# EFR32BG22 register map
Vendor: Silicon Labs; Series: EFR32; File version: C
Registers are 32-bit, read-write, reset 0x0 unless marked. A register's access mark holds for its fields unless they carry their own. Offsets are from the block's base; [hi:lo] are bit positions; lines under a group give offsets from that group; {n}, {i} and the like mark numbered series; 'fields as' and 'values as' point back to an identical list.

## GPIO_S — GPIO_S Registers
Base 0x4003C000
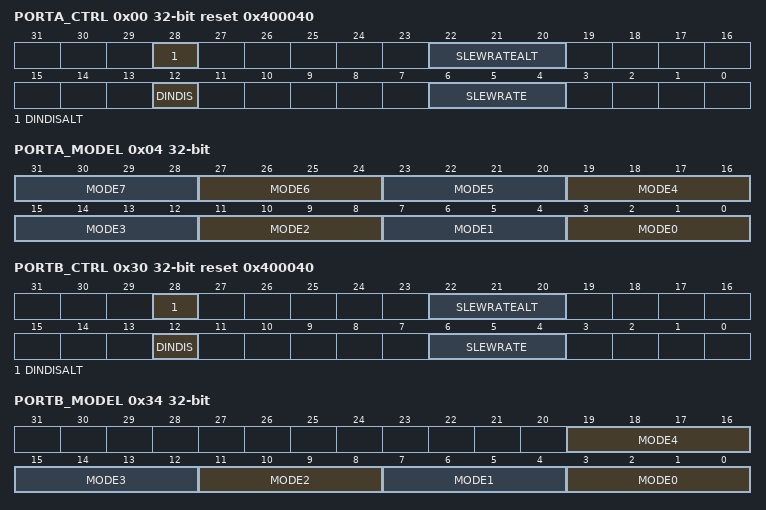
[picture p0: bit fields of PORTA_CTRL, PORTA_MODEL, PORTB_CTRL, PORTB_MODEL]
0x00 PORTA_CTRL reset 0x400040 — Port control
  [28] DINDISALT — Data In Disable Alt
  [22:20] SLEWRATEALT
  [12] DINDIS — Data In Disable
  [6:4] SLEWRATE
0x04 PORTA_MODEL — mode low
  [all] fields
    0=DISABLED (Input disabled. Pullup if DOUT is set.); 1=INPUT (Input enabled. Filter if DOUT is set.); 2=INPUTPULL (Input enabled. DOUT determines pull direction.); 3=INPUTPULLFILTER (Input enabled with filter. DOUT determines pull direction.); 4=PUSHPULL (Push-pull output.); 5=PUSHPULLALT (Push-pull using alternate control.); 6=WIREDOR (Wired-or output.); 7=WIREDORPULLDOWN (Wired-or output with pull-down.); 8=WIREDAND (Open-drain output.); 9=WIREDANDFILTER (Open-drain output with filter.); 10=WIREDANDPULLUP (Open-drain output with pullup.); 11=WIREDANDPULLUPFILTER (Open-drain output with filter and pullup.); 12=WIREDANDALT (Open-drain output using alternate control.); 13=WIREDANDALTFILTER (Open-drain output using alternate control with filter.); 14=WIREDANDALTPULLUP (Open-drain output using alternate control with pullup.); 15=WIREDANDALTPULLUPFILTER (Open-drain output using alternate control with filter and pullup.)
  [4n+3:4n] MODE{n} (n=0..7) — MODE n
0x0C PORTA_MODEH — mode high
  [3:0] MODE0 — MODE n
    values as the fields of PORTA_MODEL
0x10 PORTA_DOUT — data out
  [8:0] DOUT — Data output
0x14 PORTA_DIN ro — data in
  [8:0] DIN — Data input
0x30 PORTB_CTRL reset 0x400040 — Port control
  fields as PORTA_CTRL
0x34 PORTB_MODEL — mode low
  [all] fields
    values as the fields of PORTA_MODEL
  [4n+3:4n] MODE{n} (n=0..4) — MODE n
0x40 PORTB_DOUT — data out
  [4:0] DOUT — Data output
0x44 PORTB_DIN ro — data in
  [4:0] DIN — Data input
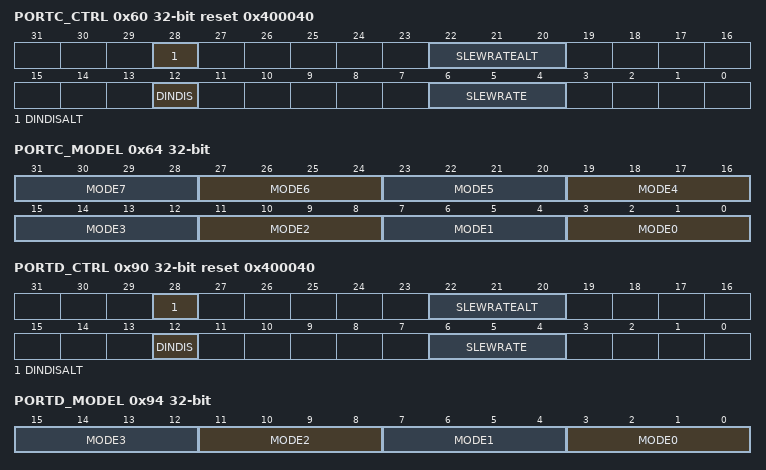
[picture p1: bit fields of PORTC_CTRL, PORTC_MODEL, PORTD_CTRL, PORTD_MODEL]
0x60 PORTC_CTRL reset 0x400040 — Port control
  fields as PORTA_CTRL
0x64 PORTC_MODEL — mode low
  fields as PORTA_MODEL
0x70 PORTC_DOUT — data out
  [7:0] DOUT — Data output
0x74 PORTC_DIN ro — data in
  [7:0] DIN — Data input
0x90 PORTD_CTRL reset 0x400040 — Port control
  fields as PORTA_CTRL
0x94 PORTD_MODEL — mode low
  [all] fields
    values as the fields of PORTA_MODEL
  [4n+3:4n] MODE{n} (n=0..3) — MODE n
0xA0 PORTD_DOUT — data out
  [3:0] DOUT — Data output
0xA4 PORTD_DIN ro — data in
  [3:0] DIN — Data input
0x300 LOCK wo reset 0xA534
  [15:0] LOCKKEY — Configuration Lock Key
    0xA534=UNLOCK (Unlock code)
0x310 GPIOLOCKSTATUS ro
  [0] LOCK — GPIO LOCK status
    0=UNLOCKED (Registers are unlocked); 1=LOCKED (Registers are locked)
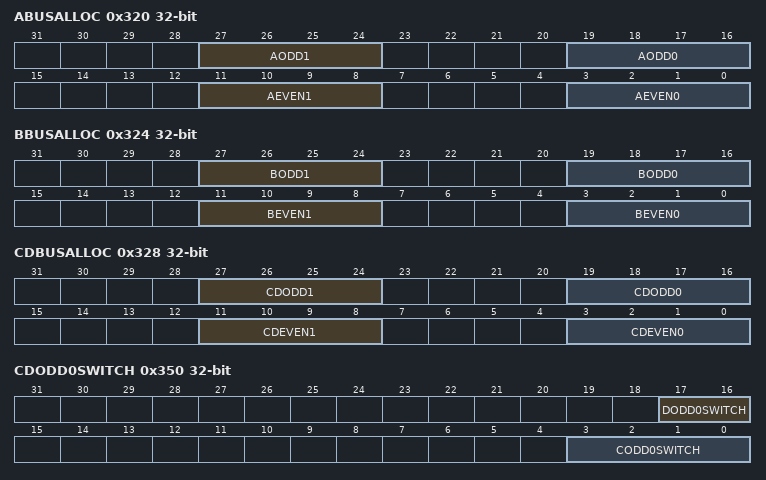
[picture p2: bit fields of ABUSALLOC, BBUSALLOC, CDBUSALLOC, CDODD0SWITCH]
0x320 ABUSALLOC — A Bus allocation
  [27:24] AODD1 — A Bus Odd 1
    0=TRISTATE (The bus is not allocated); 1=ADC0 (The bus is allocated to ADC0); 15=DEBUG (DEBUG mode, bus allocated to all clients)
  [19:16] AODD0 — A Bus Odd 0
    0=TRISTATE (The bus is not allocated); 1=ADC0 (The bus is allocated to ADC0); 14=DIAGA (The bus is allocated to DIAGA); 15=DEBUG (DEBUG mode, bus allocated to all clients)
  [11:8] AEVEN1 — A Bus Even 1
    values as AODD1
  [3:0] AEVEN0 — A Bus Even 0
    values as AODD0
0x324 BBUSALLOC — B Bus allocation
  [all] fields
    values as ABUSALLOC.AODD1
  [27:24] BODD1 — B Bus Odd 1
  [19:16] BODD0 — B Bus Odd 0
  [11:8] BEVEN1 — B Bus Even 1
  [3:0] BEVEN0 — B Bus Even 0
0x328 CDBUSALLOC — CD Bus allocation
  [27:24] CDODD1 — CD Bus Odd 1
    values as ABUSALLOC.AODD1
  [19:16] CDODD0 — CD Bus Odd 0
    0=TRISTATE (The bus is not allocated); 1=ADC0 (The bus is allocated to ADC0); 12=PMON (The bus is allocated to Process Monitor); 15=DEBUG (DEBUG mode, bus allocated to all clients)
  [11:8] CDEVEN1 — CD Bus Even 1
    values as ABUSALLOC.AODD1
  [3:0] CDEVEN0 — CD Bus Even 0
    0=TRISTATE (The bus is not allocated); 1=ADC0 (The bus is allocated to ADC0); 12=PMON (The bus is allocated to Process Monitor); 13=EFUSE (The bus is allocated for EFUSE programming voltage); 15=DEBUG (DEBUG mode, bus allocated to all clients)
0x330 AODD0SWITCH — ABUS AODD0 Switch Register
  [3:0] AODD0SWITCH
0x334 AODD1SWITCH — ABUS AODD1 Switch Register
  [3:0] AODD1SWITCH
0x338 AEVEN0SWITCH — ABUS AEVEN0 Switch Register
  [4:0] AEVEN0SWITCH
0x33C AEVEN1SWITCH — ABUS AEVEN1 Switch Register
  [4:0] AEVEN1SWITCH
0x340 BODD0SWITCH — ABUS BODD0 Switch Register
  [1:0] BODD0SWITCH — BODD0 Switch Reg
0x344 BODD1SWITCH — ABUS BODD1 Switch Register
  [1:0] BODD1SWITCH — BODD1 Switch Reg
0x348 BEVEN0SWITCH — ABUS BEVEN0 Switch Register
  [2:0] BEVEN0SWITCH
0x34C BEVEN1SWITCH — ABUS BEVEN1 Switch Register
  [2:0] BEVEN1SWITCH
0x350 CDODD0SWITCH — ABUS CDODD0 Switch Register
  [17:16] DODD0SWITCH, [3:0] CODD0SWITCH
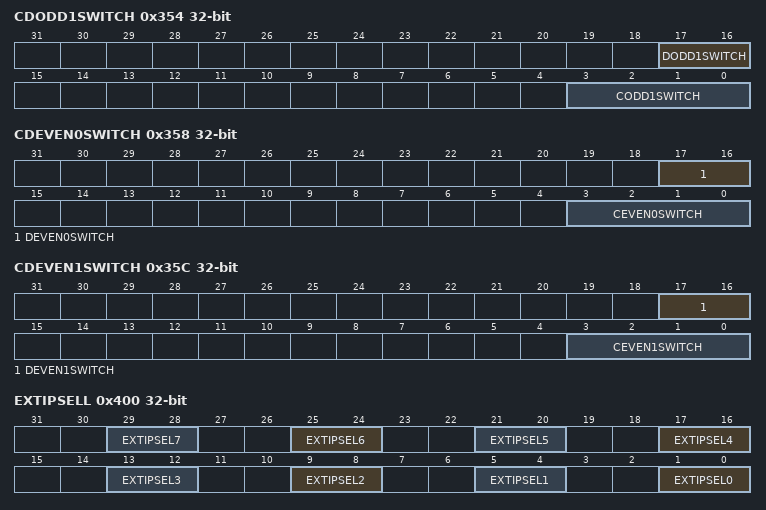
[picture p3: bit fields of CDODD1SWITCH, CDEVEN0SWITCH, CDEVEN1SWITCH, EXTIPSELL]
0x354 CDODD1SWITCH — ABUS CDODD1 Switch Register
  [17:16] DODD1SWITCH, [3:0] CODD1SWITCH
0x358 CDEVEN0SWITCH — ABUS CDEVEN0 Switch Register
  [17:16] DEVEN0SWITCH, [3:0] CEVEN0SWITCH
0x35C CDEVEN1SWITCH — ABUS CDEVEN1 Switch Register
  [17:16] DEVEN1SWITCH — DODD1 switch register
  [3:0] CEVEN1SWITCH
0x400 EXTIPSELL — External Interrupt Port Select Low
  [all] fields
    0=PORTA (Port A group selected); 1=PORTB (Port B group selected); 2=PORTC (Port C group selected); 3=PORTD (Port D group selected)
  [4n+1:4n] EXTIPSEL{n} (n=0..7) — External Interrupt Port Select
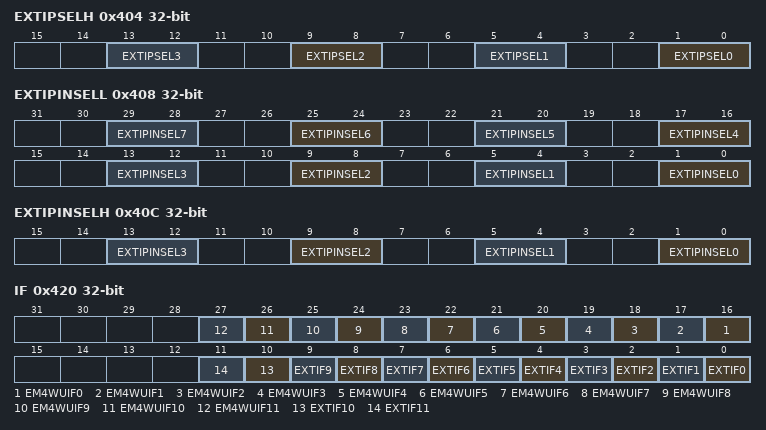
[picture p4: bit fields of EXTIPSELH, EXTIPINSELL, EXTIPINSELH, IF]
0x404 EXTIPSELH — External interrupt Port Select High
  [all] fields
    values as the fields of EXTIPSELL
  [4n+1:4n] EXTIPSEL{n} (n=0..3) — External Interrupt Port Select
0x408 EXTIPINSELL — External Interrupt Pin Select Low
  [all] fields
    {v}=OFFSET{v} (v=0..3)
  [4n+1:4n] EXTIPINSEL{n} (n=0..7) — External Interrupt Pin select
0x40C EXTIPINSELH — External Interrupt Pin Select High
  [all] fields
    {v}=OFFSET{v+8} (v=0..3)
  [4n+1:4n] EXTIPINSEL{n} (n=0..3) — External Interrupt Pin select
0x410 EXTIRISE — External Interrupt Rising Edge Trigger
  [11:0] EXTIRISE — EXT Int Rise
0x414 EXTIFALL — External Interrupt Falling Edge Trigger
  [11:0] EXTIFALL — EXT Int FALL
0x420 IF — Interrupt Flag
  [n+16] EM4WUIF{n} (n=0..11) — EM4 wake up
  [n] EXTIF{n} (n=0..11) — External Pin Flag
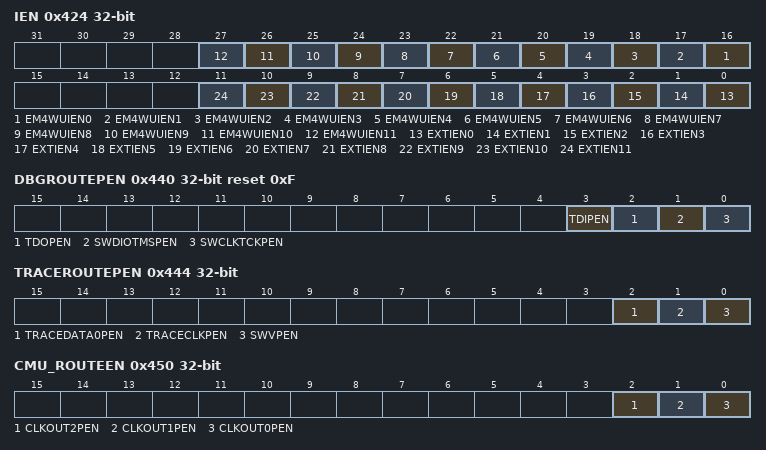
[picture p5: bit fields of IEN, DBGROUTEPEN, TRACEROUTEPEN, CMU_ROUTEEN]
0x424 IEN — Interrupt Enable
  [n+16] EM4WUIEN{n} (n=0..11) — EM4 Wake Up Interrupt En
  [n] EXTIEN{n} (n=0..11) — External Pin Enable
0x42C EM4WUEN
  [27:16] EM4WUEN — EM4 wake up enable
0x430 EM4WUPOL
  [27:16] EM4WUPOL — EM4 Wake-Up Polarity
0x440 DBGROUTEPEN reset 0xF
  [3] TDIPEN — JTAG Test Debug Input Pin Enable
  [2] TDOPEN — JTAG Test Debug Output Pin Enable
  [1] SWDIOTMSPEN — Route Location 0
  [0] SWCLKTCKPEN — Route Pin Enable
0x444 TRACEROUTEPEN
  [2] TRACEDATA0PEN — Trace Data0 Pin Enable
  [1] TRACECLKPEN — Trace Clk Pin Enable
  [0] SWVPEN — Serial Wire Viewer Output Pin Enable
0x450 CMU_ROUTEEN — CMU pin enable
  [2] CLKOUT2PEN — CLKOUT2 pin enable control bit
  [1] CLKOUT1PEN — CLKOUT1 pin enable control bit
  [0] CLKOUT0PEN — CLKOUT0 pin enable control bit
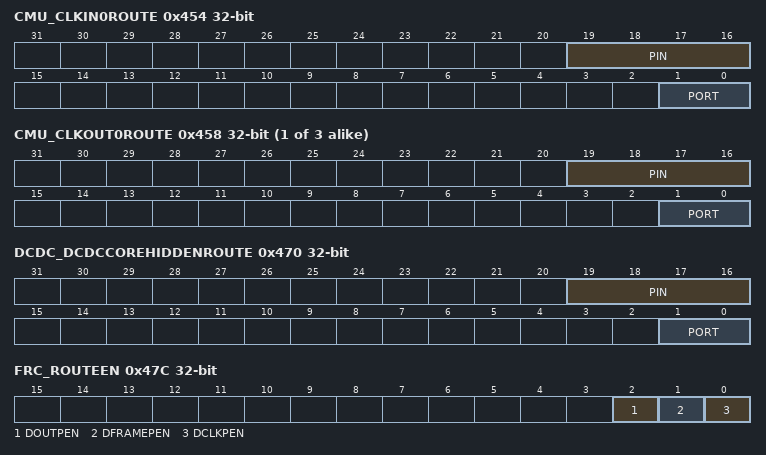
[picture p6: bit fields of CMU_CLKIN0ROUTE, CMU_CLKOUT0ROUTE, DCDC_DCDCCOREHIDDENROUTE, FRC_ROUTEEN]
0x454 CMU_CLKIN0ROUTE — CLKIN0 port/pin select
  [19:16] PIN — CLKIN0 pin select register
  [1:0] PORT — CLKIN0 port select register
{0x458+4i} CMU_CLKOUT{i}ROUTE (i=0..2) — CLKOUT{i} port/pin select
  [19:16] PIN — CLKOUT{i} pin select register
  [1:0] PORT — CLKOUT{i} port select register
0x46C DCDC_ROUTEEN — DCDC pin enable
  [0] DCDCCOREHIDDENPEN — DCDCCOREHIDDEN pin enable control bit
0x470 DCDC_DCDCCOREHIDDENROUTE — DCDCCOREHIDDEN port/pin select
  [19:16] PIN — DCDCCOREHIDDEN pin select register
  [1:0] PORT — DCDCCOREHIDDEN port select register
0x47C FRC_ROUTEEN — FRC pin enable
  [2] DOUTPEN — DOUT pin enable control bit
  [1] DFRAMEPEN — DFRAME pin enable control bit
  [0] DCLKPEN — DCLK pin enable control bit
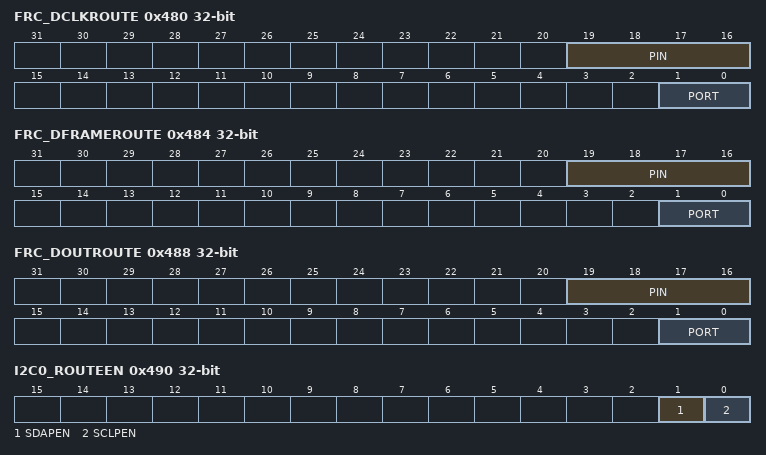
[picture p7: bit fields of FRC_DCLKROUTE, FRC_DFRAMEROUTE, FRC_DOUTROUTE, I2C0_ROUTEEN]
0x480 FRC_DCLKROUTE — DCLK port/pin select
  [19:16] PIN — DCLK pin select register
  [1:0] PORT — DCLK port select register
0x484 FRC_DFRAMEROUTE — DFRAME port/pin select
  [19:16] PIN — DFRAME pin select register
  [1:0] PORT — DFRAME port select register
0x488 FRC_DOUTROUTE — DOUT port/pin select
  [19:16] PIN — DOUT pin select register
  [1:0] PORT — DOUT port select register
0x490 I2C0_ROUTEEN — I2C0 pin enable
  [1] SDAPEN — SDA pin enable control bit
  [0] SCLPEN — SCL pin enable control bit
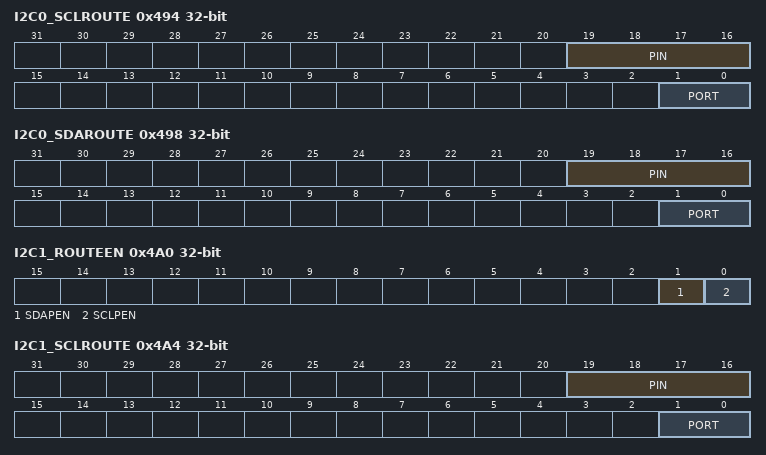
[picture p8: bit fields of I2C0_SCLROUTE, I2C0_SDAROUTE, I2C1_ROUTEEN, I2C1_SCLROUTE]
0x494 I2C0_SCLROUTE — SCL port/pin select
  [19:16] PIN — SCL pin select register
  [1:0] PORT — SCL port select register
0x498 I2C0_SDAROUTE — SDA port/pin select
  [19:16] PIN — SDA pin select register
  [1:0] PORT — SDA port select register
0x4A0 I2C1_ROUTEEN — I2C1 pin enable
  fields as I2C0_ROUTEEN
0x4A4 I2C1_SCLROUTE — SCL port/pin select
  fields as I2C0_SCLROUTE
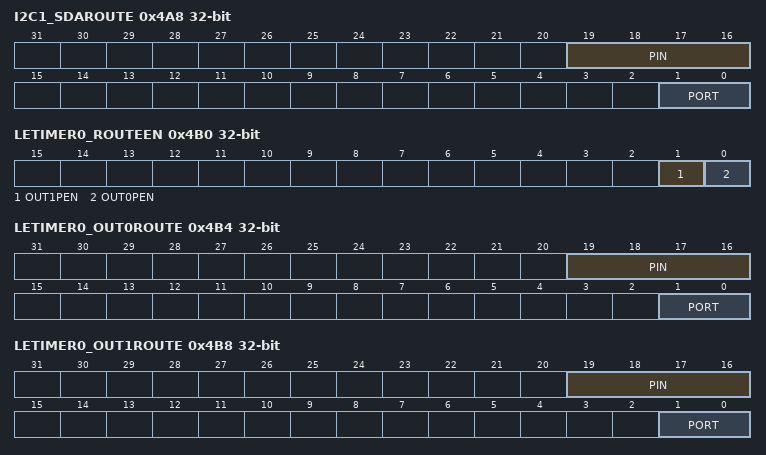
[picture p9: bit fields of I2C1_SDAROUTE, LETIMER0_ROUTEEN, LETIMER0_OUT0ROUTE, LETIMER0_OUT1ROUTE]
0x4A8 I2C1_SDAROUTE — SDA port/pin select
  fields as I2C0_SDAROUTE
0x4B0 LETIMER0_ROUTEEN — LETIMER pin enable
  [1] OUT1PEN — OUT1 pin enable control bit
  [0] OUT0PEN — OUT0 pin enable control bit
0x4B4 LETIMER0_OUT0ROUTE — OUT0 port/pin select
  [19:16] PIN — OUT0 pin select register
  [1:0] PORT — OUT0 port select register
0x4B8 LETIMER0_OUT1ROUTE — OUT1 port/pin select
  [19:16] PIN — OUT1 pin select register
  [1:0] PORT — OUT1 port select register
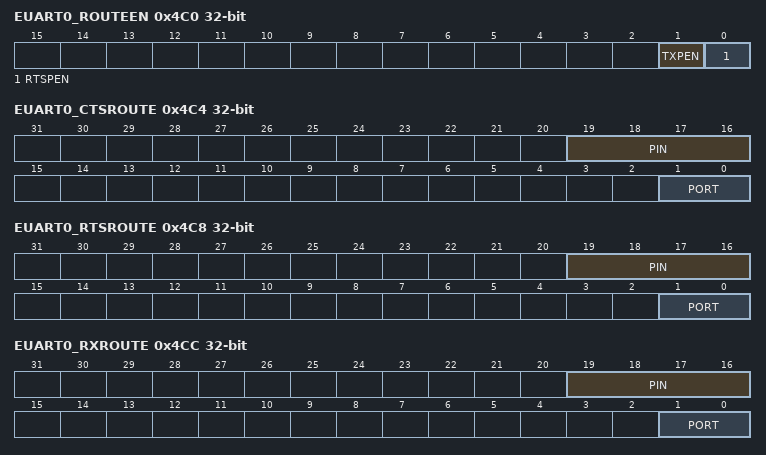
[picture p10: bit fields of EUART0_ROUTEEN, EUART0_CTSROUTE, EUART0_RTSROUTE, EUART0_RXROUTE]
0x4C0 EUART0_ROUTEEN — EUART pin enable
  [1] TXPEN — TX pin enable control bit
  [0] RTSPEN — RTS pin enable control bit
0x4C4 EUART0_CTSROUTE — CTS port/pin select
  [19:16] PIN — CTS pin select register
  [1:0] PORT — CTS port select register
0x4C8 EUART0_RTSROUTE — RTS port/pin select
  [19:16] PIN — RTS pin select register
  [1:0] PORT — RTS port select register
0x4CC EUART0_RXROUTE — RX port/pin select
  [19:16] PIN — RX pin select register
  [1:0] PORT — RX port select register
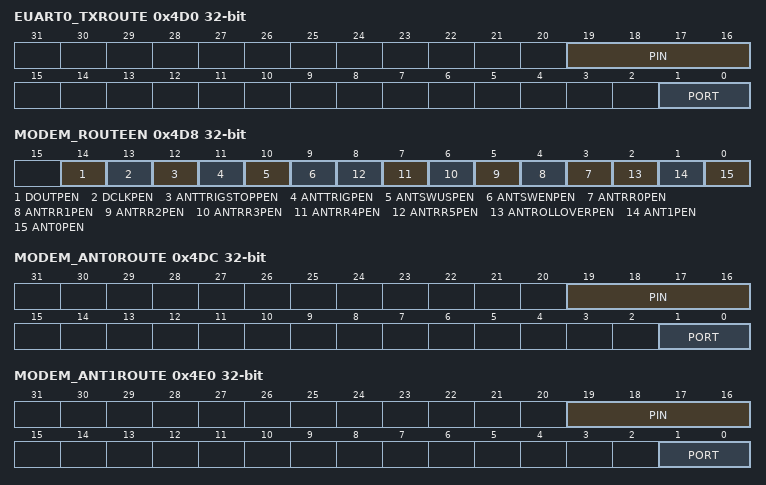
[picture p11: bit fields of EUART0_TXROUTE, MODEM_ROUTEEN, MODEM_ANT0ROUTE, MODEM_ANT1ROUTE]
0x4D0 EUART0_TXROUTE — TX port/pin select
  [19:16] PIN — TX pin select register
  [1:0] PORT — TX port select register
0x4D8 MODEM_ROUTEEN — MODEM pin enable
  [14] DOUTPEN — DOUT pin enable control bit
  [13] DCLKPEN — DCLK pin enable control bit
  [12] ANTTRIGSTOPPEN — ANTTRIGSTOP pin enable control bit
  [11] ANTTRIGPEN — ANTTRIG pin enable control bit
  [10] ANTSWUSPEN — ANTSWUS pin enable control bit
  [9] ANTSWENPEN — ANTSWEN pin enable control bit
  [n+3] ANTRR{n}PEN (n=0..5) — ANTRR{n} pin enable control bit
  [2] ANTROLLOVERPEN — ANTROLLOVER pin enable control bit
  [1] ANT1PEN — ANT1 pin enable control bit
  [0] ANT0PEN — ANT0 pin enable control bit
0x4DC MODEM_ANT0ROUTE — ANT0 port/pin select
  [19:16] PIN — ANT0 pin select register
  [1:0] PORT — ANT0 port select register
0x4E0 MODEM_ANT1ROUTE — ANT1 port/pin select
  [19:16] PIN — ANT1 pin select register
  [1:0] PORT — ANT1 port select register
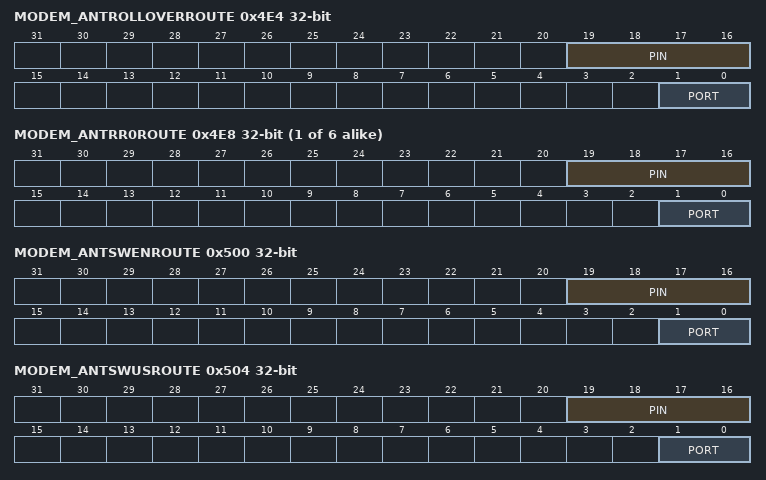
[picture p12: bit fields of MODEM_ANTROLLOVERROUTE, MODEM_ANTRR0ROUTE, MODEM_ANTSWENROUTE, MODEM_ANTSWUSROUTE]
0x4E4 MODEM_ANTROLLOVERROUTE — ANTROLLOVER port/pin select
  [19:16] PIN — ANTROLLOVER pin select register
  [1:0] PORT — ANTROLLOVER port select register
{0x4E8+4i} MODEM_ANTRR{i}ROUTE (i=0..5) — ANTRR{i} port/pin select
  [19:16] PIN — ANTRR{i} pin select register
  [1:0] PORT — ANTRR{i} port select register
0x500 MODEM_ANTSWENROUTE — ANTSWEN port/pin select
  [19:16] PIN — ANTSWEN pin select register
  [1:0] PORT — ANTSWEN port select register
0x504 MODEM_ANTSWUSROUTE — ANTSWUS port/pin select
  [19:16] PIN — ANTSWUS pin select register
  [1:0] PORT — ANTSWUS port select register
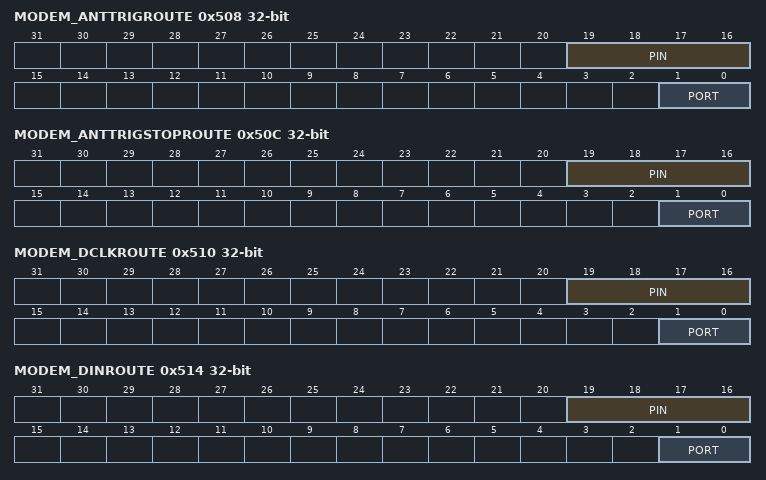
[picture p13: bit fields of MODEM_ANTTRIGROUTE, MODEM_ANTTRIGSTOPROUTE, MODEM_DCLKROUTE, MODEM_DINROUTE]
0x508 MODEM_ANTTRIGROUTE — ANTTRIG port/pin select
  [19:16] PIN — ANTTRIG pin select register
  [1:0] PORT — ANTTRIG port select register
0x50C MODEM_ANTTRIGSTOPROUTE — ANTTRIGSTOP port/pin select
  [19:16] PIN — ANTTRIGSTOP pin select register
  [1:0] PORT — ANTTRIGSTOP port select register
0x510 MODEM_DCLKROUTE — DCLK port/pin select
  fields as FRC_DCLKROUTE
0x514 MODEM_DINROUTE — DIN port/pin select
  [19:16] PIN — DIN pin select register
  [1:0] PORT — DIN port select register
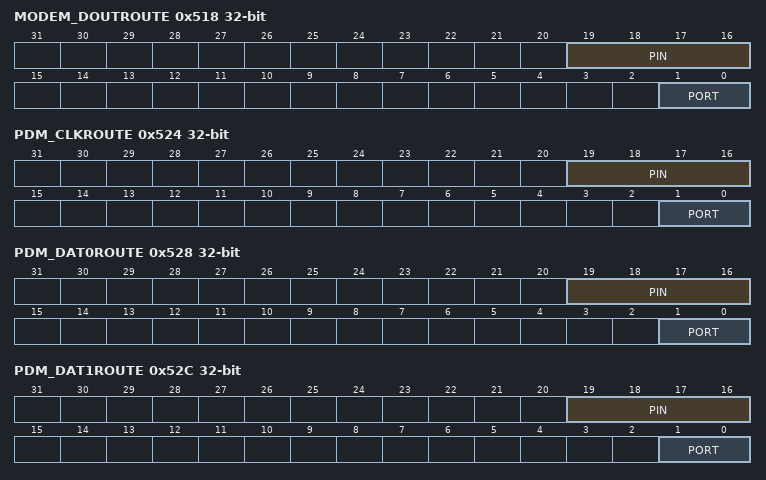
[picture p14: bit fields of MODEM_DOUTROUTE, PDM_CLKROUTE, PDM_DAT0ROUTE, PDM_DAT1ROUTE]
0x518 MODEM_DOUTROUTE — DOUT port/pin select
  fields as FRC_DOUTROUTE
0x520 PDM_ROUTEEN — PDM pin enable
  [0] CLKPEN — CLK pin enable control bit
0x524 PDM_CLKROUTE — CLK port/pin select
  [19:16] PIN — CLK pin select register
  [1:0] PORT — CLK port select register
0x528 PDM_DAT0ROUTE — DAT0 port/pin select
  [19:16] PIN — DAT0 pin select register
  [1:0] PORT — DAT0 port select register
0x52C PDM_DAT1ROUTE — DAT1 port/pin select
  [19:16] PIN — DAT1 pin select register
  [1:0] PORT — DAT1 port select register
0x534 PRS0_ROUTEEN — PRS0 pin enable
  [n+12] SYNCH{n}PEN (n=0..3) — SYNCH{n} pin enable control bit
  [n] ASYNCH{n}PEN (n=0..11) — ASYNCH{n} pin enable control bit
{0x538+4i} PRS0_ASYNCH{i}ROUTE (i=0..11) — ASYNCH{i} port/pin select
  [19:16] PIN — ASYNCH{i} pin select register
  [1:0] PORT — ASYNCH{i} port select register
{0x568+4i} PRS0_SYNCH{i}ROUTE (i=0..3) — SYNCH{i} port/pin select
  [19:16] PIN — SYNCH{i} pin select register
  [1:0] PORT — SYNCH{i} port select register
{0x57C+0x20*i} TIMER{i}_ROUTEEN (i=0..4) — TIMER{i} pin enable
  [5] CCC2PEN — CCC2 pin enable control bit
  [4] CCC1PEN — CCC1 pin enable control bit
  [3] CCC0PEN — CCC0 pin enable control bit
  [2] CC2PEN — CC2 pin enable control bit
  [1] CC1PEN — CC1 pin enable control bit
  [0] CC0PEN — CC0 pin enable control bit
{0x580+0x20*i} TIMER{i}_CC0ROUTE (i=0..4) — CC0 port/pin select
  [19:16] PIN — CC0 pin select register
  [1:0] PORT — CC0 port select register
{0x584+0x20*i} TIMER{i}_CC1ROUTE (i=0..4) — CC1 port/pin select
  [19:16] PIN — CC1 pin select register
  [1:0] PORT — CC1 port select register
{0x588+0x20*i} TIMER{i}_CC2ROUTE (i=0..4) — CC2 port/pin select
  [19:16] PIN — CC2 pin select register
  [1:0] PORT — CC2 port select register
{0x58C+0x20*i} TIMER{i}_CCC0ROUTE (i=0..4) — CCC0 port/pin select
  [19:16] PIN — CCC0 pin select register
  [1:0] PORT — CCC0 port select register
{0x590+0x20*i} TIMER{i}_CCC1ROUTE (i=0..4) — CCC1 port/pin select
  [19:16] PIN — CCC1 pin select register
  [1:0] PORT — CCC1 port select register
{0x594+0x20*i} TIMER{i}_CCC2ROUTE (i=0..4) — CCC2 port/pin select
  [19:16] PIN — CCC2 pin select register
  [1:0] PORT — CCC2 port select register
0x61C USART0_ROUTEEN — USART0 pin enable
  [4] TXPEN — TX pin enable control bit
  [3] CLKPEN — SCLK pin enable control bit
  [2] RXPEN — RX pin enable control bit
  [1] RTSPEN — RTS pin enable control bit
  [0] CSPEN — CS pin enable control bit
0x620 USART0_CSROUTE — CS port/pin select
  [19:16] PIN — CS pin select register
  [1:0] PORT — CS port select register
0x624 USART0_CTSROUTE — CTS port/pin select
  fields as EUART0_CTSROUTE
0x628 USART0_RTSROUTE — RTS port/pin select
  fields as EUART0_RTSROUTE
0x62C USART0_RXROUTE — RX port/pin select
  fields as EUART0_RXROUTE
0x630 USART0_CLKROUTE — SCLK port/pin select
  [19:16] PIN — SCLK pin select register
  [1:0] PORT — SCLK port select register
0x634 USART0_TXROUTE — TX port/pin select
  fields as EUART0_TXROUTE
0x63C USART1_ROUTEEN — USART1 pin enable
  fields as USART0_ROUTEEN
0x640 USART1_CSROUTE — CS port/pin select
  fields as USART0_CSROUTE
0x644 USART1_CTSROUTE — CTS port/pin select
  fields as EUART0_CTSROUTE
0x648 USART1_RTSROUTE — RTS port/pin select
  fields as EUART0_RTSROUTE
0x64C USART1_RXROUTE — RX port/pin select
  fields as EUART0_RXROUTE
0x650 USART1_CLKROUTE — SCLK port/pin select
  fields as USART0_CLKROUTE
0x654 USART1_TXROUTE — TX port/pin select
  fields as EUART0_TXROUTE
